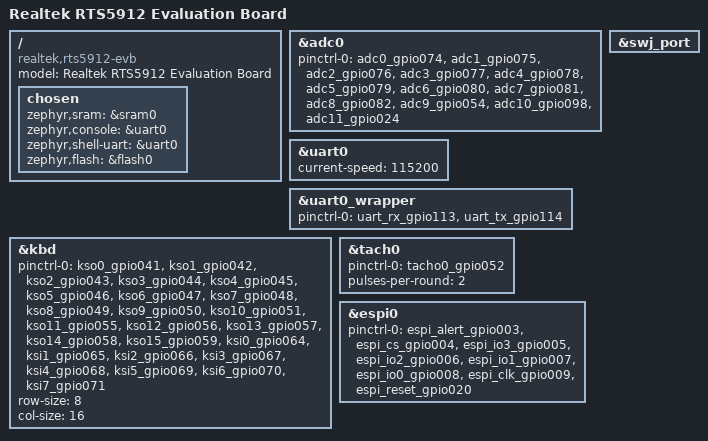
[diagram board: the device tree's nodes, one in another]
/*
 * SPDX-License-Identifier: Apache-2.0
 *
 * Copyright (c) 2024 Realtek Semiconductor Corporation, SIBG-SD7
 *
 */

/dts-v1/;
#include <realtek/ec/rts5912.dtsi>
#include <realtek/ec/rts5912-pinctrl.dtsi>
#include <zephyr/dt-bindings/gpio/gpio.h>
/ {
	model = "Realtek RTS5912 Evaluation Board";
	compatible = "realtek,rts5912-evb";

	chosen {
		zephyr,sram = &sram0;
		zephyr,console = &uart0;
		zephyr,shell-uart = &uart0;
		zephyr,flash = &flash0;
	};
};

&adc0 {
	status = "okay";
	pinctrl-0 = <&adc0_gpio074 &adc1_gpio075
		&adc2_gpio076 &adc3_gpio077
		&adc4_gpio078 &adc5_gpio079
		&adc6_gpio080 &adc7_gpio081
		&adc8_gpio082 &adc9_gpio054
		&adc10_gpio098 &adc11_gpio024>;
	pinctrl-names = "default";
};

&uart0 {
	status = "okay";
	current-speed = <115200>;
};

&uart0_wrapper {
	status = "okay";
	pinctrl-0 = <&uart_rx_gpio113 &uart_tx_gpio114>;
	pinctrl-names = "default";
};

&kbd {
	status = "okay";
	pinctrl-0 = <&kso0_gpio041 &kso1_gpio042
		     &kso2_gpio043 &kso3_gpio044
		     &kso4_gpio045 &kso5_gpio046
		     &kso6_gpio047 &kso7_gpio048
		     &kso8_gpio049 &kso9_gpio050
		     &kso10_gpio051 &kso11_gpio055
		     &kso12_gpio056 &kso13_gpio057
		     &kso14_gpio058 &kso15_gpio059
		     &ksi0_gpio064 &ksi1_gpio065
		     &ksi2_gpio066 &ksi3_gpio067
		     &ksi4_gpio068 &ksi5_gpio069
		     &ksi6_gpio070 &ksi7_gpio071>;
	pinctrl-names = "default";
	row-size = <8>;
	col-size = <16>;
};

&swj_port {
	status = "okay";
};

&tach0 {
	status = "okay";
	pinctrl-0 = <&tacho0_gpio052>;
	pinctrl-names = "default";
	pulses-per-round = <2>;
};

&espi0 {
	status = "okay";
	pinctrl-0 = < &espi_alert_gpio003 &espi_cs_gpio004
				&espi_io3_gpio005 &espi_io2_gpio006
				&espi_io1_gpio007 &espi_io0_gpio008
				&espi_clk_gpio009 &espi_reset_gpio020>;
	pinctrl-names = "default";
};
